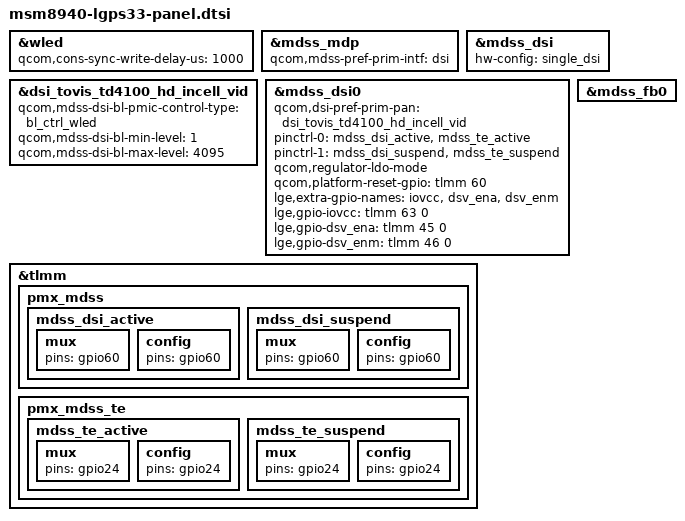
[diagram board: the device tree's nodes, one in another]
/*
 * Copyright (c) 2016, The Linux Foundation. All rights reserved.
 *
 * This program is free software; you can redistribute it and/or modify
 * it under the terms of the GNU General Public License version 2 and
 * only version 2 as published by the Free Software Foundation.
 *
 * This program is distributed in the hope that it will be useful,
 * but WITHOUT ANY WARRANTY; without even the implied warranty of
 * MERCHANTABILITY or FITNESS FOR A PARTICULAR PURPOSE.  See the
 * GNU General Public License for more details.
 */

#include "../dsi-panel-tovis-ph1_td4100-720p-video.dtsi"

&wled {
	qcom,cons-sync-write-delay-us = <1000>;
};

&mdss_mdp {
	qcom,mdss-pref-prim-intf = "dsi";
};

&mdss_dsi {
	hw-config = "single_dsi";
};

&dsi_tovis_td4100_hd_incell_vid {
	qcom,mdss-dsi-bl-pmic-control-type = "bl_ctrl_wled";
	qcom,mdss-dsi-bl-min-level = <1>;
	qcom,mdss-dsi-bl-max-level = <4095>;
};

&mdss_dsi0 {
	qcom,dsi-pref-prim-pan = <&dsi_tovis_td4100_hd_incell_vid>;
	pinctrl-names = "mdss_default", "mdss_sleep";
	pinctrl-0 = <&mdss_dsi_active &mdss_te_active>;
	pinctrl-1 = <&mdss_dsi_suspend &mdss_te_suspend>;
	qcom,regulator-ldo-mode;
	qcom,platform-reset-gpio = <&tlmm 60 0>;

	lge,extra-gpio-names = "iovcc", "dsv_ena", "dsv_enm";
	lge,gpio-iovcc = <&tlmm 63 0>;
	lge,gpio-dsv_ena = <&tlmm 45 0>;
	lge,gpio-dsv_enm = <&tlmm 46 0>;
};

&mdss_fb0 {
	/delete-property/ qcom,mdss-fb-splash-logo-enabled;
};

&tlmm {
	pmx_mdss {
		mdss_dsi_active: mdss_dsi_active {
			mux {
				pins = "gpio60";
			};

			config {
				pins = "gpio60";
			};
		};

		mdss_dsi_suspend: mdss_dsi_suspend {
			mux {
				pins = "gpio60";
			};

			config {
				pins = "gpio60";
			};
		};
	};

	pmx_mdss_te {
		mdss_te_active: mdss_te_active {
			mux {
				pins = "gpio24";
			};

			config {
				pins = "gpio24";
			};
		};

		mdss_te_suspend: mdss_te_suspend {
			mux {
				pins = "gpio24";
			};

			config {
				pins = "gpio24";
			};
		};
	};
};
